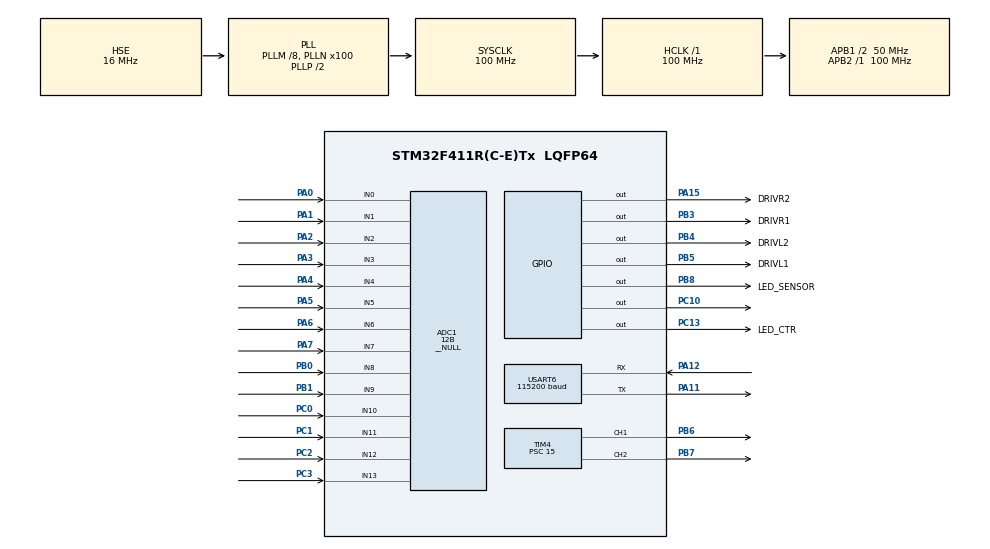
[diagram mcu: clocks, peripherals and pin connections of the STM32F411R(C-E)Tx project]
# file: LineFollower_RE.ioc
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ADC1.Channel-1\#ChannelRegularConversion=ADC_CHANNEL_0
ADC1.Channel-10\#ChannelRegularConversion=ADC_CHANNEL_9
ADC1.Channel-11\#ChannelRegularConversion=ADC_CHANNEL_10
ADC1.Channel-12\#ChannelRegularConversion=ADC_CHANNEL_11
ADC1.Channel-13\#ChannelRegularConversion=ADC_CHANNEL_12
ADC1.Channel-14\#ChannelRegularConversion=ADC_CHANNEL_13
ADC1.Channel-2\#ChannelRegularConversion=ADC_CHANNEL_1
ADC1.Channel-3\#ChannelRegularConversion=ADC_CHANNEL_2
ADC1.Channel-4\#ChannelRegularConversion=ADC_CHANNEL_3
ADC1.Channel-5\#ChannelRegularConversion=ADC_CHANNEL_4
ADC1.Channel-6\#ChannelRegularConversion=ADC_CHANNEL_5
ADC1.Channel-7\#ChannelRegularConversion=ADC_CHANNEL_6
ADC1.Channel-8\#ChannelRegularConversion=ADC_CHANNEL_7
ADC1.Channel-9\#ChannelRegularConversion=ADC_CHANNEL_8
ADC1.Channel-IN0=ADC_CHANNEL_0
ADC1.Channel-IN1=ADC_CHANNEL_1
ADC1.Channel-IN2=ADC_CHANNEL_2
ADC1.Channel-IN3=ADC_CHANNEL_3
ADC1.Channel-IN4=ADC_CHANNEL_4
ADC1.Channel-IN5=ADC_CHANNEL_5
ADC1.Channel-IN6=ADC_CHANNEL_6
ADC1.Channel-IN7=ADC_CHANNEL_7
ADC1.Channel-IN8=ADC_CHANNEL_8
ADC1.Channel-IN9=ADC_CHANNEL_9
ADC1.ClockPrescaler=ADC_CLOCK_SYNC_PCLK_DIV4
ADC1.ContinuousConvMode=DISABLE
ADC1.DMAContinuousRequests=DISABLE
ADC1.DataAlign=ADC_DATAALIGN_RIGHT
ADC1.DiscontinuousConvMode=DISABLE
ADC1.EOCSelection=ADC_EOC_SINGLE_CONV
ADC1.EnableAnalogWatchDog=false
ADC1.ExternalTrigConv=ADC_SOFTWARE_START
ADC1.ExternalTrigConvEdge=ADC_EXTERNALTRIGCONVEDGE_NONE
ADC1.InjNumberOfConversion=0
ADC1.Mode=__NULL
ADC1.NbrOfConversion=14
ADC1.Rank-1\#ChannelRegularConversion=1
ADC1.Rank-10\#ChannelRegularConversion=10
ADC1.Rank-11\#ChannelRegularConversion=11
ADC1.Rank-12\#ChannelRegularConversion=12
ADC1.Rank-13\#ChannelRegularConversion=13
ADC1.Rank-14\#ChannelRegularConversion=14
ADC1.Rank-2\#ChannelRegularConversion=2
ADC1.Rank-3\#ChannelRegularConversion=3
ADC1.Rank-4\#ChannelRegularConversion=4
ADC1.Rank-5\#ChannelRegularConversion=5
ADC1.Rank-6\#ChannelRegularConversion=6
ADC1.Rank-7\#ChannelRegularConversion=7
ADC1.Rank-8\#ChannelRegularConversion=8
ADC1.Rank-9\#ChannelRegularConversion=9
ADC1.Resolution=ADC_RESOLUTION_12B
ADC1.SamplingTime-1\#ChannelRegularConversion=ADC_SAMPLETIME_112CYCLES
ADC1.SamplingTime-10\#ChannelRegularConversion=ADC_SAMPLETIME_112CYCLES
ADC1.SamplingTime-11\#ChannelRegularConversion=ADC_SAMPLETIME_112CYCLES
ADC1.SamplingTime-12\#ChannelRegularConversion=ADC_SAMPLETIME_112CYCLES
ADC1.SamplingTime-13\#ChannelRegularConversion=ADC_SAMPLETIME_112CYCLES
ADC1.SamplingTime-14\#ChannelRegularConversion=ADC_SAMPLETIME_112CYCLES
ADC1.SamplingTime-2\#ChannelRegularConversion=ADC_SAMPLETIME_112CYCLES
ADC1.SamplingTime-3\#ChannelRegularConversion=ADC_SAMPLETIME_112CYCLES
ADC1.SamplingTime-4\#ChannelRegularConversion=ADC_SAMPLETIME_112CYCLES
ADC1.SamplingTime-5\#ChannelRegularConversion=ADC_SAMPLETIME_112CYCLES
ADC1.SamplingTime-6\#ChannelRegularConversion=ADC_SAMPLETIME_112CYCLES
ADC1.SamplingTime-7\#ChannelRegularConversion=ADC_SAMPLETIME_112CYCLES
ADC1.SamplingTime-8\#ChannelRegularConversion=ADC_SAMPLETIME_112CYCLES
ADC1.SamplingTime-9\#ChannelRegularConversion=ADC_SAMPLETIME_112CYCLES
ADC1.ScanConvMode=ENABLE
ADC1.master=1
Dma.Request0=USART6_RX
Dma.USART6_RX.0.Direction=DMA_PERIPH_TO_MEMORY
Dma.USART6_RX.0.FIFOMode=DMA_FIFOMODE_DISABLE
Dma.USART6_RX.0.Instance=DMA2_Stream1
Dma.USART6_RX.0.MemDataAlignment=DMA_MDATAALIGN_BYTE
Dma.USART6_RX.0.MemInc=DMA_MINC_ENABLE
Dma.USART6_RX.0.Mode=DMA_NORMAL
Dma.USART6_RX.0.PeriphDataAlignment=DMA_PDATAALIGN_BYTE
Dma.USART6_RX.0.PeriphInc=DMA_PINC_DISABLE
Dma.USART6_RX.0.Priority=DMA_PRIORITY_LOW
FREERTOS.BinarySemaphores01=CommSemaphore,Dynamic,NULL
FREERTOS.HEAP_NUMBER=4
FREERTOS.INCLUDE_eTaskGetState=0
FREERTOS.INCLUDE_pcTaskGetTaskName=0
FREERTOS.INCLUDE_uxTaskGetStackHighWaterMark=0
FREERTOS.INCLUDE_uxTaskGetStackHighWaterMark2=0
FREERTOS.INCLUDE_uxTaskPriorityGet=1
FREERTOS.INCLUDE_vTaskCleanUpResources=0
FREERTOS.INCLUDE_vTaskDelay=1
FREERTOS.INCLUDE_vTaskDelayUntil=0
FREERTOS.INCLUDE_vTaskDelete=1
FREERTOS.INCLUDE_vTaskPrioritySet=1
FREERTOS.INCLUDE_vTaskSuspend=1
FREERTOS.INCLUDE_xEventGroupSetBitFromISR=0
FREERTOS.INCLUDE_xQueueGetMutexHolder=0
FREERTOS.INCLUDE_xSemaphoreGetMutexHolder=0
FREERTOS.INCLUDE_xTaskAbortDelay=0
FREERTOS.INCLUDE_xTaskGetCurrentTaskHandle=0
FREERTOS.INCLUDE_xTaskGetHandle=0
FREERTOS.INCLUDE_xTaskResumeFromISR=1
FREERTOS.MEMORY_ALLOCATION=2
FREERTOS.Tasks01=defaultTask,0,128,StartDefaultTask,Default,NULL,Dynamic,NULL,NULL;CommTask,-3,128,StartCommTask,Default,NULL,Dynamic,NULL,NULL;DriveTask,-3,128,StartDriveTask,Default,NULL,Dynamic,NULL,NULL
FREERTOS.configCHECK_FOR_STACK_OVERFLOW=0
FREERTOS.configENABLE_BACKWARD_COMPATIBILITY=1
FREERTOS.configENABLE_FPU=0
FREERTOS.configGENERATE_RUN_TIME_STATS=0
FREERTOS.configIDLE_SHOULD_YIELD=1
FREERTOS.configLIBRARY_LOWEST_INTERRUPT_PRIORITY=15
FREERTOS.configLIBRARY_MAX_SYSCALL_INTERRUPT_PRIORITY=5
FREERTOS.configMAX_CO_ROUTINE_PRIORITIES=2
FREERTOS.configMAX_PRIORITIES=7
FREERTOS.configMAX_TASK_NAME_LEN=16
FREERTOS.configMINIMAL_STACK_SIZE=128
FREERTOS.configQUEUE_REGISTRY_SIZE=8
FREERTOS.configRECORD_STACK_HIGH_ADDRESS=0
FREERTOS.configTICK_RATE_HZ=1000
FREERTOS.configTOTAL_HEAP_SIZE=15360
FREERTOS.configUSE_APPLICATION_TASK_TAG=0
FREERTOS.configUSE_COUNTING_SEMAPHORES=0
FREERTOS.configUSE_CO_ROUTINES=0
FREERTOS.configUSE_DAEMON_TASK_STARTUP_HOOK=0
FREERTOS.configUSE_IDLE_HOOK=0
FREERTOS.configUSE_MALLOC_FAILED_HOOK=0
FREERTOS.configUSE_MUTEXES=1
FREERTOS.configUSE_NEWLIB_REENTRANT=0
FREERTOS.configUSE_POSIX_ERRNO=0
FREERTOS.configUSE_PREEMPTION=1
FREERTOS.configUSE_RECURSIVE_MUTEXES=0
FREERTOS.configUSE_STATS_FORMATTING_FUNCTIONS=0
FREERTOS.configUSE_TASK_NOTIFICATIONS=1
FREERTOS.configUSE_TICKLESS_IDLE=0
FREERTOS.configUSE_TICK_HOOK=0
FREERTOS.configUSE_TIMERS=0
FREERTOS.configUSE_TRACE_FACILITY=0
FREERTOS.copyHeapFile=1
Mcu.Family=STM32F4
Mcu.Name=STM32F411R(C-E)Tx
Mcu.Package=LQFP64
NVIC.DMA2_Stream1_IRQn=true\:5\:0\:false\:false\:true\:true\:false\:true\:true
NVIC.PriorityGroup=NVIC_PRIORITYGROUP_4
NVIC.TIM1_UP_TIM10_IRQn=true\:15\:0\:false\:false\:true\:false\:true\:true\:true
NVIC.TIM4_IRQn=true\:10\:0\:true\:false\:true\:true\:true\:true\:true
NVIC.TimeBase=TIM1_UP_TIM10_IRQn
NVIC.TimeBaseIP=TIM10
NVIC.USART6_IRQn=true\:5\:0\:false\:false\:true\:true\:true\:true\:true
PA0-WKUP.Signal=ADCx_IN0
PA1.Signal=ADCx_IN1
PA11.Mode=Asynchronous
PA11.Signal=USART6_TX
PA12.Mode=Asynchronous
PA12.Signal=USART6_RX
PA13.Mode=Serial_Wire
PA13.Signal=SYS_JTMS-SWDIO
PA14.Mode=Serial_Wire
PA14.Signal=SYS_JTCK-SWCLK
PA15.GPIO_Label=DRIVR2
PA15.Signal=GPIO_Output
PA2.Signal=ADCx_IN2
PA3.Signal=ADCx_IN3
PA4.Signal=ADCx_IN4
PA5.Signal=ADCx_IN5
PA6.Signal=ADCx_IN6
PA7.Signal=ADCx_IN7
PB0.Signal=ADCx_IN8
PB1.Signal=ADCx_IN9
PB3.GPIO_Label=DRIVR1
PB3.Signal=GPIO_Output
PB4.GPIO_Label=DRIVL2
PB4.Signal=GPIO_Output
PB5.GPIO_Label=DRIVL1
PB5.Signal=GPIO_Output
PB6.Signal=S_TIM4_CH1
PB7.Signal=S_TIM4_CH2
PB8.GPIO_Label=LED_SENSOR
PB8.Signal=GPIO_Output
PC0.Signal=ADCx_IN10
PC1.Signal=ADCx_IN11
PC10.Signal=GPIO_Output
PC13-ANTI_TAMP.GPIO_Label=LED_CTR
PC13-ANTI_TAMP.GPIO_PuPd=GPIO_PULLUP
PC13-ANTI_TAMP.Signal=GPIO_Output
PC2.Signal=ADCx_IN12
PC3.Signal=ADCx_IN13
PH0\ -\ OSC_IN.Mode=HSE-External-Oscillator
PH0\ -\ OSC_IN.Signal=RCC_OSC_IN
PH1\ -\ OSC_OUT.Mode=HSE-External-Oscillator
PH1\ -\ OSC_OUT.Signal=RCC_OSC_OUT
ProjectManager.HeapSize=0x200
ProjectManager.StackSize=0x400
ProjectManager.TargetToolchain=Makefile
RCC.48MHZClocksFreq_Value=50000000
RCC.AHBFreq_Value=100000000
RCC.APB1CLKDivider=RCC_HCLK_DIV2
RCC.APB1Freq_Value=50000000
RCC.APB1TimFreq_Value=100000000
RCC.APB2Freq_Value=100000000
RCC.APB2TimFreq_Value=100000000
RCC.CortexFreq_Value=100000000
RCC.HCLKFreq_Value=100000000
RCC.HSE_VALUE=16000000
RCC.HSI_VALUE=16000000
RCC.LSE_VALUE=32768
RCC.PLLM=8
RCC.PLLN=100
RCC.PLLSourceVirtual=RCC_PLLSOURCE_HSE
RCC.SYSCLKFreq_VALUE=100000000
RCC.SYSCLKSource=RCC_SYSCLKSOURCE_PLLCLK
RCC.VCOOutputFreq_Value=200000000
SH.ADCx_IN0.0=ADC1_IN0,IN0
SH.ADCx_IN1.0=ADC1_IN1,IN1
SH.ADCx_IN10.0=ADC1_IN10,IN10
SH.ADCx_IN11.0=ADC1_IN11,IN11
SH.ADCx_IN12.0=ADC1_IN12,IN12
SH.ADCx_IN13.0=ADC1_IN13,IN13
SH.ADCx_IN2.0=ADC1_IN2,IN2
SH.ADCx_IN3.0=ADC1_IN3,IN3
SH.ADCx_IN4.0=ADC1_IN4,IN4
SH.ADCx_IN5.0=ADC1_IN5,IN5
SH.ADCx_IN6.0=ADC1_IN6,IN6
SH.ADCx_IN7.0=ADC1_IN7,IN7
SH.ADCx_IN8.0=ADC1_IN8,IN8
SH.ADCx_IN9.0=ADC1_IN9,IN9
SH.S_TIM4_CH1.0=TIM4_CH1,PWM Generation1 CH1
SH.S_TIM4_CH2.0=TIM4_CH2,PWM Generation2 CH2
TIM4.AutoReloadPreload=TIM_AUTORELOAD_PRELOAD_ENABLE
TIM4.Channel-PWM\ Generation1\ CH1=TIM_CHANNEL_1
TIM4.Channel-PWM\ Generation2\ CH2=TIM_CHANNEL_2
TIM4.ClockDivision=TIM_CLOCKDIVISION_DIV1
TIM4.CounterMode=TIM_COUNTERMODE_UP
TIM4.OC1Preload_PWM=ENABLE
TIM4.OC2Preload_PWM=ENABLE
TIM4.OCFastMode_PWM-PWM\ Generation1\ CH1=TIM_OCFAST_DISABLE
TIM4.OCFastMode_PWM-PWM\ Generation2\ CH2=TIM_OCFAST_DISABLE
TIM4.OCMode_PWM-PWM\ Generation1\ CH1=TIM_OCMODE_PWM1
TIM4.OCMode_PWM-PWM\ Generation2\ CH2=TIM_OCMODE_PWM1
TIM4.OCPolarity_1=TIM_OCPOLARITY_HIGH
TIM4.OCPolarity_2=TIM_OCPOLARITY_HIGH
TIM4.Period=19
TIM4.Prescaler=15
TIM4.Pulse-PWM\ Generation1\ CH1=0
TIM4.Pulse-PWM\ Generation2\ CH2=0
TIM4.TIM_MasterOutputTrigger=TIM_TRGO_RESET
TIM4.TIM_MasterSlaveMode=TIM_MASTERSLAVEMODE_DISABLE
USART6.BaudRate=115200
USART6.Mode=MODE_TX_RX
USART6.OverSampling=UART_OVERSAMPLING_16
USART6.Parity=PARITY_NONE
USART6.StopBits=STOPBITS_1
USART6.VirtualMode=VM_ASYNC
USART6.WordLength=WORDLENGTH_8B
VP_FREERTOS_VS_CMSIS_V1.Mode=CMSIS_V1
VP_SYS_VS_tim10.Mode=TIM10
board=custom

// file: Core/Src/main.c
/* USER CODE BEGIN Header */
/**
  ******************************************************************************
  * @file           : main.c
  * @brief          : Main program body
  ******************************************************************************
  * @attention
  *
  * Copyright (c) 2023 STMicroelectronics.
  * All rights reserved.
  *
  * This software is licensed under terms that can be found in the LICENSE file
  * in the root directory of this software component.
  * If no LICENSE file comes with this software, it is provided AS-IS.
  *
  ******************************************************************************
  */
/* USER CODE END Header */
#include "main.h"
#include "cmsis_os.h"
#include "adc.h"
#include "dma.h"
#include "tim.h"
#include "usart.h"
#include "gpio.h"

void SystemClock_Config(void);
void MX_FREERTOS_Init(void);

int main(void)
{

  /* MCU Configuration--------------------------------------------------------*/

  /* Reset of all peripherals, Initializes the Flash interface and the Systick. */
  HAL_Init();

  /* Configure the system clock */
  SystemClock_Config();

  /* Initialize all configured peripherals */
  MX_GPIO_Init();
  MX_DMA_Init();
  MX_ADC1_Init();
  MX_TIM4_Init();
  MX_USART6_UART_Init();
  /* USER CODE BEGIN 2 */
  HAL_TIM_PWM_Start(&htim4, TIM_CHANNEL_1);
  HAL_TIM_PWM_Start(&htim4, TIM_CHANNEL_2);
  /* USER CODE END 2 */

  /* Call init function for freertos objects (in freertos.c) */
  MX_FREERTOS_Init();

  /* Start scheduler */
  osKernelStart();
  /* We should never get here as control is now taken by the scheduler */
  /* Infinite loop */
  while (1)
  {

  }
}

void SystemClock_Config(void)
{
  RCC_OscInitTypeDef RCC_OscInitStruct = {0};
  RCC_ClkInitTypeDef RCC_ClkInitStruct = {0};

  /** Configure the main internal regulator output voltage
  */
  __HAL_RCC_PWR_CLK_ENABLE();
  __HAL_PWR_VOLTAGESCALING_CONFIG(PWR_REGULATOR_VOLTAGE_SCALE1);

  /** Initializes the RCC Oscillators according to the specified parameters
  * in the RCC_OscInitTypeDef structure.
  */
  RCC_OscInitStruct.OscillatorType = RCC_OSCILLATORTYPE_HSE;
  RCC_OscInitStruct.HSEState = RCC_HSE_ON;
  RCC_OscInitStruct.PLL.PLLState = RCC_PLL_ON;
  RCC_OscInitStruct.PLL.PLLSource = RCC_PLLSOURCE_HSE;
  RCC_OscInitStruct.PLL.PLLM = 8;
  RCC_OscInitStruct.PLL.PLLN = 100;
  RCC_OscInitStruct.PLL.PLLP = RCC_PLLP_DIV2;
  RCC_OscInitStruct.PLL.PLLQ = 4;
  if (HAL_RCC_OscConfig(&RCC_OscInitStruct) != HAL_OK)
  {
    Error_Handler();
  }

  /** Initializes the CPU, AHB and APB buses clocks
  */
  RCC_ClkInitStruct.ClockType = RCC_CLOCKTYPE_HCLK|RCC_CLOCKTYPE_SYSCLK
                              |RCC_CLOCKTYPE_PCLK1|RCC_CLOCKTYPE_PCLK2;
  RCC_ClkInitStruct.SYSCLKSource = RCC_SYSCLKSOURCE_PLLCLK;
  RCC_ClkInitStruct.AHBCLKDivider = RCC_SYSCLK_DIV1;
  RCC_ClkInitStruct.APB1CLKDivider = RCC_HCLK_DIV2;
  RCC_ClkInitStruct.APB2CLKDivider = RCC_HCLK_DIV1;

  if (HAL_RCC_ClockConfig(&RCC_ClkInitStruct, FLASH_LATENCY_3) != HAL_OK)
  {
    Error_Handler();
  }
}

void HAL_TIM_PeriodElapsedCallback(TIM_HandleTypeDef *htim)
{
  if (htim->Instance == TIM10) {
    HAL_IncTick();
  }
}

void Error_Handler(void)
{
  __disable_irq();
  while (1)
  {
  }
}

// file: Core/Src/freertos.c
/* USER CODE BEGIN Header */
/**
  ******************************************************************************
  * File Name          : freertos.c
  * Description        : Code for freertos applications
  ******************************************************************************
  * @attention
  *
  * Copyright (c) 2023 STMicroelectronics.
  * All rights reserved.
  *
  * This software is licensed under terms that can be found in the LICENSE file
  * in the root directory of this software component.
  * If no LICENSE file comes with this software, it is provided AS-IS.
  *
  ******************************************************************************
  */
/* USER CODE END Header */

#include "FreeRTOS.h"
#include "task.h"
#include "main.h"
#include "cmsis_os.h"

/* USER CODE BEGIN Includes */
//#include "driver.c"
//#include "comm.h"
/* USER CODE END Includes */

osThreadId defaultTaskHandle;
osThreadId CommTaskHandle;
osThreadId DriveTaskHandle;
osSemaphoreId CommSemaphoreHandle;

void StartDefaultTask(void const * argument);
void StartCommTask(void const * argument);
void StartDriveTask(void const * argument);

void MX_FREERTOS_Init(void); /* (MISRA C 2004 rule 8.1) */

/* GetIdleTaskMemory prototype (linked to static allocation support) */
void vApplicationGetIdleTaskMemory( StaticTask_t **ppxIdleTaskTCBBuffer, StackType_t **ppxIdleTaskStackBuffer, uint32_t *pulIdleTaskStackSize );

/* USER CODE BEGIN GET_IDLE_TASK_MEMORY */
static StaticTask_t xIdleTaskTCBBuffer;
static StackType_t xIdleStack[configMINIMAL_STACK_SIZE];

void vApplicationGetIdleTaskMemory( StaticTask_t **ppxIdleTaskTCBBuffer, StackType_t **ppxIdleTaskStackBuffer, uint32_t *pulIdleTaskStackSize )
{
  *ppxIdleTaskTCBBuffer = &xIdleTaskTCBBuffer;
  *ppxIdleTaskStackBuffer = &xIdleStack[0];
  *pulIdleTaskStackSize = configMINIMAL_STACK_SIZE;
  /* place for user code */
}
/* USER CODE END GET_IDLE_TASK_MEMORY */

void MX_FREERTOS_Init(void) {

  /* Create the semaphores(s) */
  /* definition and creation of CommSemaphore */
  osSemaphoreDef(CommSemaphore);
  CommSemaphoreHandle = osSemaphoreCreate(osSemaphore(CommSemaphore), 1);

  /* Create the thread(s) */
  /* definition and creation of defaultTask */
  osThreadDef(defaultTask, StartDefaultTask, osPriorityNormal, 0, 128);
  defaultTaskHandle = osThreadCreate(osThread(defaultTask), NULL);

  /* definition and creation of CommTask */
  osThreadDef(CommTask, StartCommTask, osPriorityIdle, 0, 128);
  CommTaskHandle = osThreadCreate(osThread(CommTask), NULL);

  /* definition and creation of DriveTask */
  osThreadDef(DriveTask, StartDriveTask, osPriorityIdle, 0, 128);
  DriveTaskHandle = osThreadCreate(osThread(DriveTask), NULL);

}

void StartDefaultTask(void const * argument)
{
  for(;;)
  {
    osDelay(1);
  }
}

void StartCommTask(void const * argument)
{
  /* USER CODE BEGIN StartCommTask */
  /* Infinite loop */
  ExStartCommTask(argument);
  for(;;)
  {
    osDelay(1);
  }
  /* USER CODE END StartCommTask */
}

void StartDriveTask(void const * argument)
{
  /* USER CODE BEGIN StartDriveTask */
  /* Infinite loop */
  ExStartDriveTask(argument);
  for(;;)
  {
    osDelay(1);
  }
  /* USER CODE END StartDriveTask */
}
